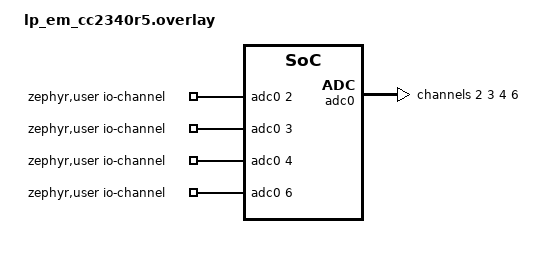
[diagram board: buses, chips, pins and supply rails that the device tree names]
/*
 * ADC channels for MicroPython's machine.ADC on the LP-EM-CC2340R5.
 * The pins are already routed to the ADC by the board file (adc0_ch0..ch8).
 * Channel number -> pin: 2 = DIO5, 3 = DIO2, 4 = DIO1, 6 = DIO25.
 * Used as: -DEXTRA_DTC_OVERLAY_FILE=<this file>
 */
#include <zephyr/dt-bindings/adc/adc.h>

/ {
	zephyr,user {
		io-channels = <&adc0 2>, <&adc0 3>, <&adc0 4>, <&adc0 6>;
	};
};

&adc0 {
	status = "okay";
	#address-cells = <1>;
	#size-cells = <0>;

	channel@2 {
		reg = <2>;
		zephyr,gain = "ADC_GAIN_1";
		zephyr,reference = "ADC_REF_VDD_1";
		zephyr,vref-mv = <3300>;
		zephyr,acquisition-time = <ADC_ACQ_TIME_DEFAULT>;
		zephyr,resolution = <12>;
	};
	channel@3 {
		reg = <3>;
		zephyr,gain = "ADC_GAIN_1";
		zephyr,reference = "ADC_REF_VDD_1";
		zephyr,vref-mv = <3300>;
		zephyr,acquisition-time = <ADC_ACQ_TIME_DEFAULT>;
		zephyr,resolution = <12>;
	};
	channel@4 {
		reg = <4>;
		zephyr,gain = "ADC_GAIN_1";
		zephyr,reference = "ADC_REF_VDD_1";
		zephyr,vref-mv = <3300>;
		zephyr,acquisition-time = <ADC_ACQ_TIME_DEFAULT>;
		zephyr,resolution = <12>;
	};
	channel@6 {
		reg = <6>;
		zephyr,gain = "ADC_GAIN_1";
		zephyr,reference = "ADC_REF_VDD_1";
		zephyr,vref-mv = <3300>;
		zephyr,acquisition-time = <ADC_ACQ_TIME_DEFAULT>;
		zephyr,resolution = <12>;
	};
};
